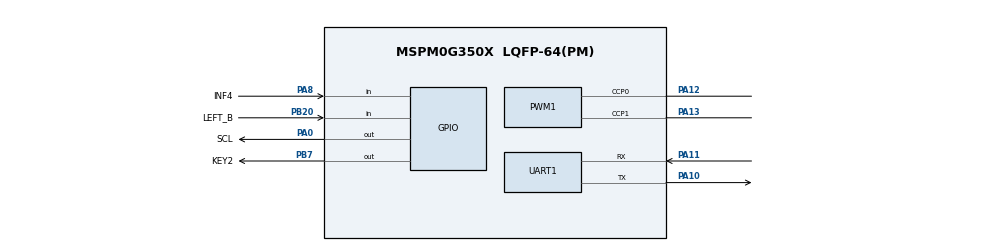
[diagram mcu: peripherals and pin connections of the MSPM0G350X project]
/**
 * @cliArgs --device "MSPM0G350X" --part "Default" --package "LQFP-64(PM)" --product "mspm0_sdk@2.05.00.05"
 * @versions {"tool":"1.24.0+4110"}
 */

/**
 * Import the modules used in this configuration.
 */
const GPIO    = scripting.addModule("/ti/driverlib/GPIO", {}, false);
const GPIO1   = GPIO.addInstance();
const GPIO2   = GPIO.addInstance();
const GPIO3   = GPIO.addInstance();
const GPIO4   = GPIO.addInstance();
const GPIO5   = GPIO.addInstance();
const GPIO6   = GPIO.addInstance();
const GPIO7   = GPIO.addInstance();
const PWM     = scripting.addModule("/ti/driverlib/PWM", {}, false);
const PWM1    = PWM.addInstance();
const SYSCTL  = scripting.addModule("/ti/driverlib/SYSCTL");
const SYSTICK = scripting.addModule("/ti/driverlib/SYSTICK");
const TIMER   = scripting.addModule("/ti/driverlib/TIMER", {}, false);
const TIMER1  = TIMER.addInstance();
const UART    = scripting.addModule("/ti/driverlib/UART", {}, false);
const UART1   = UART.addInstance();
const UART2   = UART.addInstance();

/**
 * Write custom configuration values to the imported modules.
 */
const divider7       = system.clockTree["PLL_PDIV"];
divider7.divideValue = 2;

const divider9       = system.clockTree["UDIV"];
divider9.divideValue = 2;

const gate7  = system.clockTree["MFCLKGATE"];
gate7.enable = true;

const multiplier2         = system.clockTree["PLL_QDIV"];
multiplier2.multiplyValue = 5;

const mux8       = system.clockTree["HSCLKMUX"];
mux8.inputSelect = "HSCLKMUX_SYSPLL2X";

GPIO1.$name                              = "ENCODER";
GPIO1.associatedPins.create(4);
GPIO1.associatedPins[0].$name            = "LEFT_A";
GPIO1.associatedPins[0].direction        = "INPUT";
GPIO1.associatedPins[0].internalResistor = "PULL_DOWN";
GPIO1.associatedPins[0].interruptEn      = true;
GPIO1.associatedPins[0].polarity         = "RISE";
GPIO1.associatedPins[0].assignedPort     = "PORTA";
GPIO1.associatedPins[0].assignedPin      = "28";
GPIO1.associatedPins[1].$name            = "RIGHT_A";
GPIO1.associatedPins[1].direction        = "INPUT";
GPIO1.associatedPins[1].internalResistor = "PULL_DOWN";
GPIO1.associatedPins[1].interruptEn      = true;
GPIO1.associatedPins[1].polarity         = "RISE";
GPIO1.associatedPins[1].assignedPin      = "9";
GPIO1.associatedPins[1].assignedPort     = "PORTB";
GPIO1.associatedPins[2].$name            = "LEFT_B";
GPIO1.associatedPins[2].direction        = "INPUT";
GPIO1.associatedPins[2].internalResistor = "PULL_UP";
GPIO1.associatedPins[2].polarity         = "FALL";
GPIO1.associatedPins[2].assignedPin      = "20";
GPIO1.associatedPins[2].assignedPort     = "PORTB";
GPIO1.associatedPins[2].pin.$assign      = "PB20";
GPIO1.associatedPins[3].$name            = "RIGHT_B";
GPIO1.associatedPins[3].direction        = "INPUT";
GPIO1.associatedPins[3].internalResistor = "PULL_UP";
GPIO1.associatedPins[3].polarity         = "FALL";
GPIO1.associatedPins[3].assignedPin      = "3";
GPIO1.associatedPins[3].assignedPort     = "PORTB";

const Board = scripting.addModule("/ti/driverlib/Board", {}, false);

GPIO2.$name                         = "MOTOR";
GPIO2.port                          = "PORTA";
GPIO2.associatedPins.create(4);
GPIO2.associatedPins[0].$name       = "AIN1";
GPIO2.associatedPins[1].$name       = "AIN2";
GPIO2.associatedPins[2].$name       = "BIN1";
GPIO2.associatedPins[2].assignedPin = "22";
GPIO2.associatedPins[3].$name       = "BIN2";
GPIO2.associatedPins[3].assignedPin = "15";

GPIO3.$name                              = "KEY";
GPIO3.port                               = "PORTB";
GPIO3.associatedPins.create(2);
GPIO3.associatedPins[0].$name            = "KEY1";
GPIO3.associatedPins[0].direction        = "INPUT";
GPIO3.associatedPins[0].assignedPort     = "PORTB";
GPIO3.associatedPins[0].assignedPin      = "21";
GPIO3.associatedPins[0].internalResistor = "PULL_DOWN";
GPIO3.associatedPins[1].$name            = "KEY2";
GPIO3.associatedPins[1].internalResistor = "PULL_DOWN";
GPIO3.associatedPins[1].assignedPin      = "7";
GPIO3.associatedPins[1].pin.$assign      = "PB7";

GPIO4.$name                              = "INF";
GPIO4.associatedPins.create(8);
GPIO4.associatedPins[0].$name            = "INF1";
GPIO4.associatedPins[0].direction        = "INPUT";
GPIO4.associatedPins[0].internalResistor = "PULL_DOWN";
GPIO4.associatedPins[0].assignedPin      = "8";
GPIO4.associatedPins[0].assignedPort     = "PORTB";
GPIO4.associatedPins[1].$name            = "INF2";
GPIO4.associatedPins[1].direction        = "INPUT";
GPIO4.associatedPins[1].internalResistor = "PULL_DOWN";
GPIO4.associatedPins[1].assignedPin      = "26";
GPIO4.associatedPins[1].assignedPort     = "PORTA";
GPIO4.associatedPins[2].$name            = "INF3";
GPIO4.associatedPins[2].direction        = "INPUT";
GPIO4.associatedPins[2].internalResistor = "PULL_DOWN";
GPIO4.associatedPins[2].assignedPin      = "25";
GPIO4.associatedPins[2].assignedPort     = "PORTA";
GPIO4.associatedPins[3].$name            = "INF4";
GPIO4.associatedPins[3].direction        = "INPUT";
GPIO4.associatedPins[3].internalResistor = "PULL_DOWN";
GPIO4.associatedPins[3].assignedPort     = "PORTA";
GPIO4.associatedPins[3].assignedPin      = "8";
GPIO4.associatedPins[3].pin.$assign      = "PA8";
GPIO4.associatedPins[4].$name            = "INF5";
GPIO4.associatedPins[4].direction        = "INPUT";
GPIO4.associatedPins[4].internalResistor = "PULL_DOWN";
GPIO4.associatedPins[4].assignedPin      = "19";
GPIO4.associatedPins[4].assignedPort     = "PORTB";
GPIO4.associatedPins[5].$name            = "INF6";
GPIO4.associatedPins[5].direction        = "INPUT";
GPIO4.associatedPins[5].internalResistor = "PULL_DOWN";
GPIO4.associatedPins[5].assignedPin      = "18";
GPIO4.associatedPins[5].assignedPort     = "PORTB";
GPIO4.associatedPins[6].$name            = "INF7";
GPIO4.associatedPins[6].direction        = "INPUT";
GPIO4.associatedPins[6].internalResistor = "PULL_DOWN";
GPIO4.associatedPins[6].assignedPin      = "6";
GPIO4.associatedPins[6].assignedPort     = "PORTB";
GPIO4.associatedPins[7].$name            = "INF8";
GPIO4.associatedPins[7].direction        = "INPUT";
GPIO4.associatedPins[7].internalResistor = "PULL_DOWN";
GPIO4.associatedPins[7].assignedPort     = "PORTA";
GPIO4.associatedPins[7].assignedPin      = "9";

GPIO5.$name                          = "LED";
GPIO5.associatedPins[0].$name        = "LED1";
GPIO5.associatedPins[0].assignedPort = "PORTB";
GPIO5.associatedPins[0].assignedPin  = "22";

GPIO6.$name                          = "OLED";
GPIO6.port                           = "PORTA";
GPIO6.associatedPins.create(2);
GPIO6.associatedPins[0].$name        = "SCL";
GPIO6.associatedPins[0].initialValue = "SET";
GPIO6.associatedPins[0].assignedPin  = "0";
GPIO6.associatedPins[0].ioStructure  = "OD";
GPIO6.associatedPins[0].pin.$assign  = "PA0";
GPIO6.associatedPins[1].$name        = "SDA";
GPIO6.associatedPins[1].initialValue = "SET";
GPIO6.associatedPins[1].assignedPin  = "1";
GPIO6.associatedPins[1].ioStructure  = "OD";

GPIO7.$name                              = "BUZZ";
GPIO7.port                               = "PORTA";
GPIO7.associatedPins[0].$name            = "BUZZ_1";
GPIO7.associatedPins[0].internalResistor = "PULL_DOWN";
GPIO7.associatedPins[0].assignedPin      = "5";

PWM1.$name                              = "PWM_MOTOR";
PWM1.timerCount                         = 8000;
PWM1.clockPrescale                      = 10;
PWM1.timerStartTimer                    = true;
PWM1.pwmMode                            = "EDGE_ALIGN_UP";
PWM1.peripheral.ccp0Pin.$assign         = "PA12";
PWM1.peripheral.ccp1Pin.$assign         = "PA13";
PWM1.PWM_CHANNEL_0.$name                = "ti_driverlib_pwm_PWMTimerCC0";
PWM1.PWM_CHANNEL_1.$name                = "ti_driverlib_pwm_PWMTimerCC1";
PWM1.ccp0PinConfig.direction            = scripting.forceWrite("OUTPUT");
PWM1.ccp0PinConfig.hideOutputInversion  = scripting.forceWrite(false);
PWM1.ccp0PinConfig.onlyInternalResistor = scripting.forceWrite(false);
PWM1.ccp0PinConfig.passedPeripheralType = scripting.forceWrite("Digital");
PWM1.ccp0PinConfig.$name                = "ti_driverlib_gpio_GPIOPinGeneric4";
PWM1.ccp1PinConfig.direction            = scripting.forceWrite("OUTPUT");
PWM1.ccp1PinConfig.hideOutputInversion  = scripting.forceWrite(false);
PWM1.ccp1PinConfig.onlyInternalResistor = scripting.forceWrite(false);
PWM1.ccp1PinConfig.passedPeripheralType = scripting.forceWrite("Digital");
PWM1.ccp1PinConfig.$name                = "ti_driverlib_gpio_GPIOPinGeneric6";

SYSCTL.forceDefaultClkConfig = true;
SYSCTL.validateClkStatus     = true;
SYSCTL.clockTreeEn           = true;
scripting.suppress("For best practices when the CPUCLK is running at 32MHz and above, clear the flash status bit using DL_FlashCTL_executeClearStatus\\(\\) before executing any flash operation\\. Otherwise there may be false positives\\.", SYSCTL);

SYSTICK.periodEnable  = true;
SYSTICK.systickEnable = true;
SYSTICK.period        = 1600000;

TIMER1.$name              = "TIMER_0";
TIMER1.timerMode          = "PERIODIC";
TIMER1.timerPeriod        = "20 ms";
TIMER1.timerClkPrescale   = 256;
TIMER1.timerClkDiv        = 7;
TIMER1.timerStartTimer    = true;
TIMER1.interrupts         = ["ZERO"];
TIMER1.interruptPriority  = "0";
TIMER1.peripheral.$assign = "TIMA1";

UART1.$name                            = "UART1";
UART1.enabledInterrupts                = ["RX","TX"];
UART1.peripheral.rxPin.$assign         = "PA11";
UART1.peripheral.txPin.$assign         = "PA10";
UART1.txPinConfig.direction            = scripting.forceWrite("OUTPUT");
UART1.txPinConfig.hideOutputInversion  = scripting.forceWrite(false);
UART1.txPinConfig.onlyInternalResistor = scripting.forceWrite(false);
UART1.txPinConfig.passedPeripheralType = scripting.forceWrite("Digital");
UART1.txPinConfig.$name                = "ti_driverlib_gpio_GPIOPinGeneric0";
UART1.rxPinConfig.hideOutputInversion  = scripting.forceWrite(false);
UART1.rxPinConfig.onlyInternalResistor = scripting.forceWrite(false);
UART1.rxPinConfig.passedPeripheralType = scripting.forceWrite("Digital");
UART1.rxPinConfig.$name                = "ti_driverlib_gpio_GPIOPinGeneric1";

UART2.uartClkSrc                       = "MFCLK";
UART2.targetBaudRate                   = 115200;
UART2.$name                            = "UART0";
UART2.txPinConfig.direction            = scripting.forceWrite("OUTPUT");
UART2.txPinConfig.hideOutputInversion  = scripting.forceWrite(false);
UART2.txPinConfig.onlyInternalResistor = scripting.forceWrite(false);
UART2.txPinConfig.passedPeripheralType = scripting.forceWrite("Digital");
UART2.txPinConfig.$name                = "ti_driverlib_gpio_GPIOPinGeneric2";
UART2.rxPinConfig.hideOutputInversion  = scripting.forceWrite(false);
UART2.rxPinConfig.onlyInternalResistor = scripting.forceWrite(false);
UART2.rxPinConfig.passedPeripheralType = scripting.forceWrite("Digital");
UART2.rxPinConfig.$name                = "ti_driverlib_gpio_GPIOPinGeneric3";

/**
 * Pinmux solution for unlocked pins/peripherals. This ensures that minor changes to the automatic solver in a future
 * version of the tool will not impact the pinmux you originally saw.  These lines can be completely deleted in order to
 * re-solve from scratch.
 */
GPIO1.associatedPins[0].pin.$suggestSolution = "PA28";
GPIO1.associatedPins[1].pin.$suggestSolution = "PB9";
GPIO1.associatedPins[3].pin.$suggestSolution = "PB3";
Board.peripheral.$suggestSolution            = "DEBUGSS";
Board.peripheral.swclkPin.$suggestSolution   = "PA20";
Board.peripheral.swdioPin.$suggestSolution   = "PA19";
GPIO2.associatedPins[0].pin.$suggestSolution = "PA16";
GPIO2.associatedPins[1].pin.$suggestSolution = "PA14";
GPIO2.associatedPins[2].pin.$suggestSolution = "PA22";
GPIO2.associatedPins[3].pin.$suggestSolution = "PA15";
GPIO3.associatedPins[0].pin.$suggestSolution = "PB21";
GPIO4.associatedPins[0].pin.$suggestSolution = "PB8";
GPIO4.associatedPins[1].pin.$suggestSolution = "PA26";
GPIO4.associatedPins[2].pin.$suggestSolution = "PA25";
GPIO4.associatedPins[4].pin.$suggestSolution = "PB19";
GPIO4.associatedPins[5].pin.$suggestSolution = "PB18";
GPIO4.associatedPins[6].pin.$suggestSolution = "PB6";
GPIO4.associatedPins[7].pin.$suggestSolution = "PA9";
GPIO5.associatedPins[0].pin.$suggestSolution = "PB22";
GPIO6.associatedPins[1].pin.$suggestSolution = "PA1";
GPIO7.associatedPins[0].pin.$suggestSolution = "PA5";
PWM1.peripheral.$suggestSolution             = "TIMG0";
UART1.peripheral.$suggestSolution            = "UART0";
UART2.peripheral.$suggestSolution            = "UART1";
UART2.peripheral.rxPin.$suggestSolution      = "PA18";
UART2.peripheral.txPin.$suggestSolution      = "PA17";
